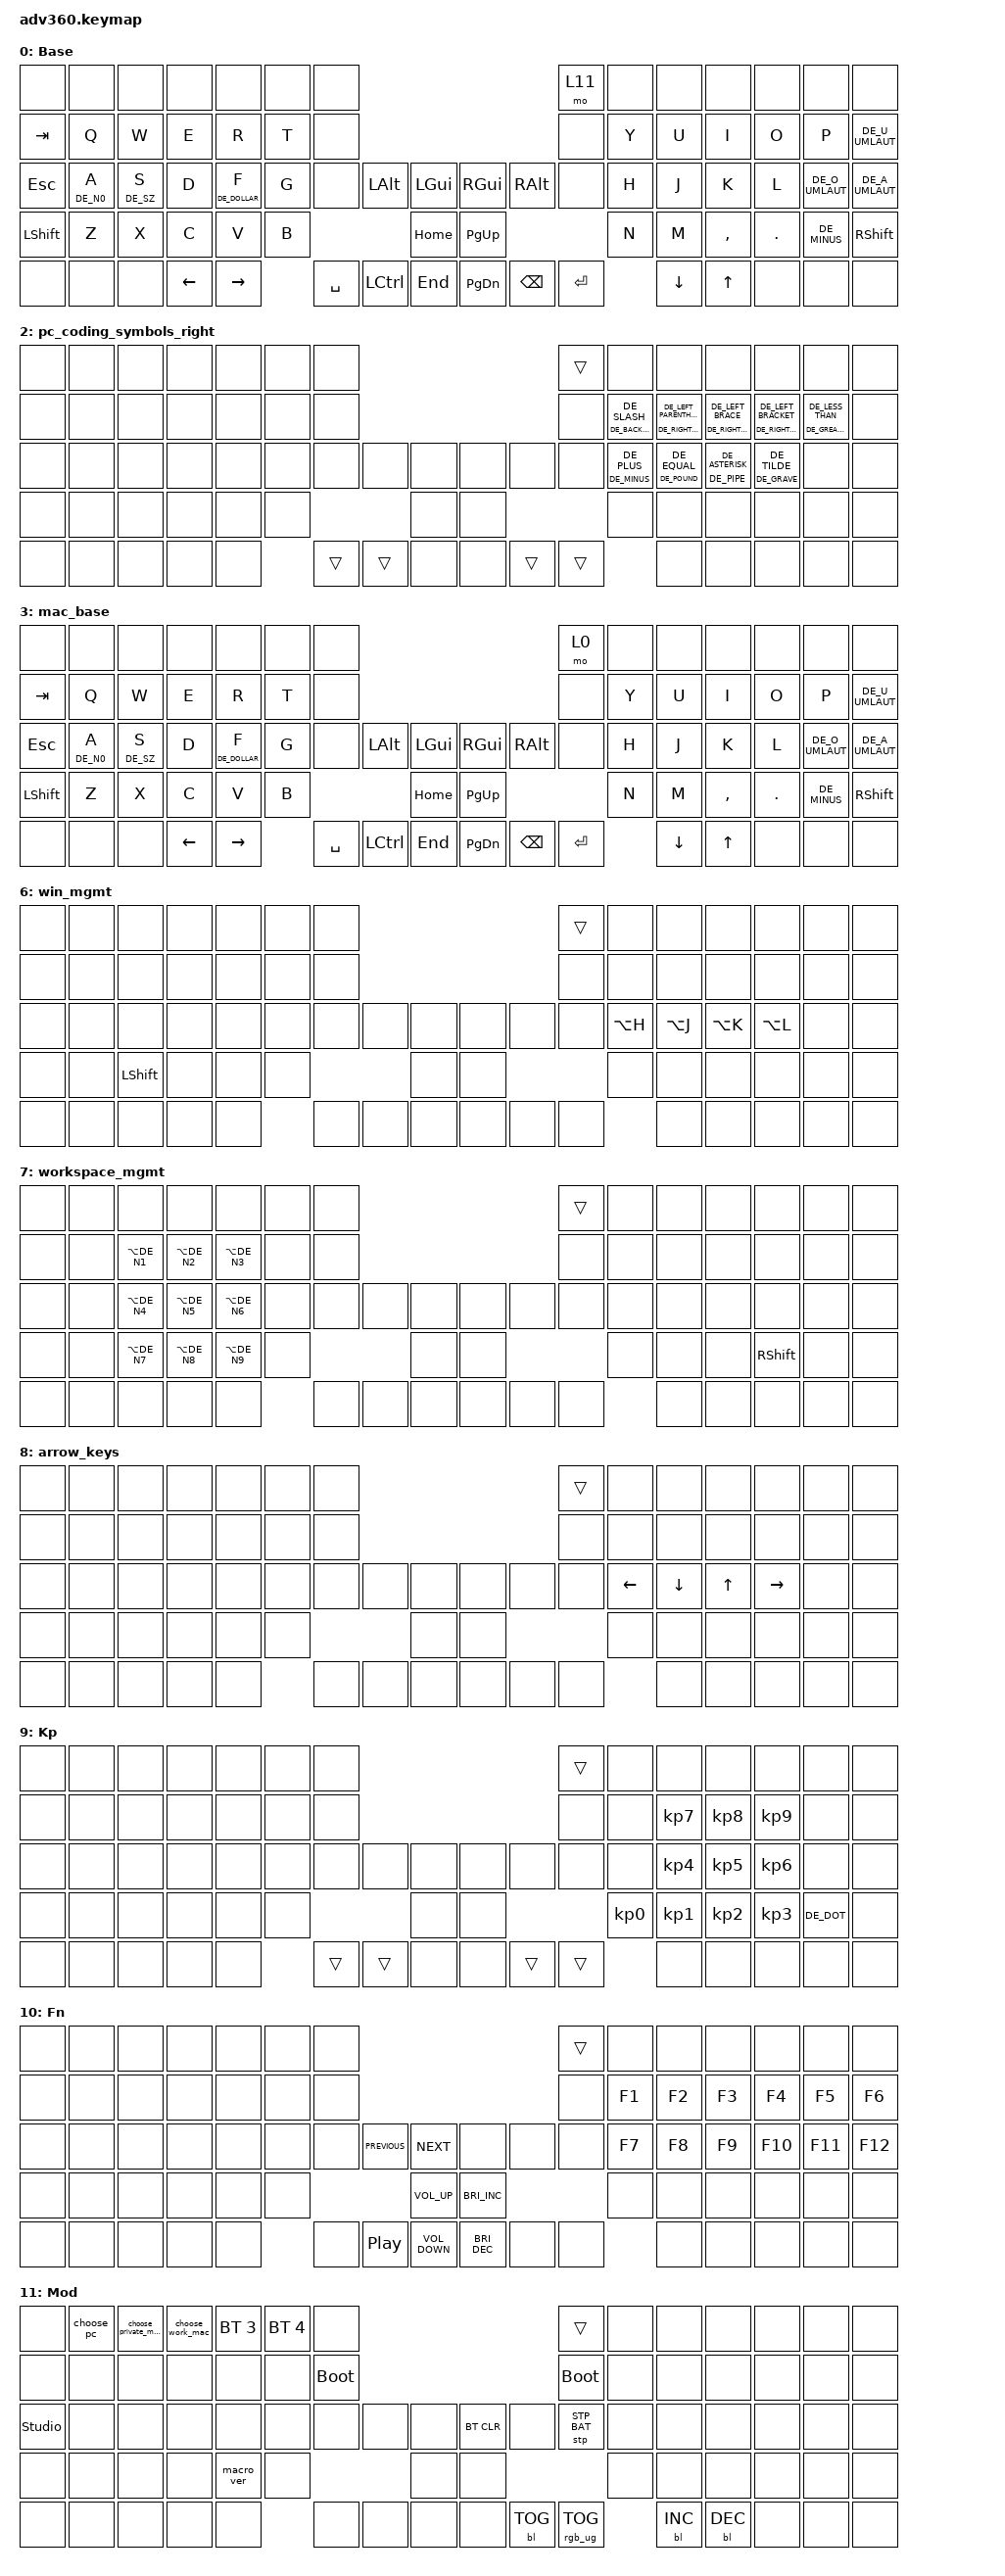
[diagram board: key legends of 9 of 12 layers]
#include <dt-bindings/zmk/stp.h>
#include <behaviors.dtsi>
#include <dt-bindings/zmk/backlight.h>
#include <dt-bindings/zmk/bt.h>
#include <dt-bindings/zmk/keys.h>
#include <dt-bindings/zmk/rgb.h>
#include "keys_de.h"

/ {
    behaviors {
        #include "macros.dtsi"
      #include "version.dtsi"

        hm: homerow_mods {
            compatible = "zmk,behavior-hold-tap";
            label = "HOMEROW_MODS";
            #binding-cells = <2>;
            tapping-term-ms = <200>;
            quick_tap_ms = <175>;
            flavor = "tap-preferred";
            bindings = <&kp>, <&kp>;
        };

        hold_alternative: hold_alternative {
            compatible = "zmk,behavior-hold-tap";
            label = "HOLD_ALTERNATIVE";
            bindings = <&kp>, <&kp>;

            #binding-cells = <2>;
            tapping-term-ms = <250>;
            flavor = "tap-preferred";
        };
    };

    macros {
        choose_work_mac: choose_mac {
            compatible = "zmk,behavior-macro";
            #binding-cells = <0>;
            bindings = <&bt BT_SEL 2 &tog 3>;
            label = "CHOOSE_MAC";
        };

        choose_pc: choose_pc {
            compatible = "zmk,behavior-macro";
            #binding-cells = <0>;
            bindings = <&bt BT_SEL 0 &tog 0>;
            label = "CHOOSE_PC";
        };

        choose_private_mac: choose_private_mac {
            compatible = "zmk,behavior-macro";
            #binding-cells = <0>;
            bindings = <&bt BT_SEL 1 &tog 3>;
            label = "CHOOSE_PRIVATE_MAC";
        };
    };

    combos {
        compatible = "zmk,combos";

        toggle_coding_symbols_right {
            bindings = <&mo 2>;
            key-positions = <32 31>;
        };

        toggle_coding_symbols_left {
            bindings = <&mo 1>;
            key-positions = <41 42>;
        };

        toggle_keypad {
            bindings = <&mo 9>;
            key-positions = <29 30>;
        };

        toggle_fn {
            bindings = <&mo 10>;
            key-positions = <47 48>;
        };

        toggle_win_mgmt {
            bindings = <&mo 9>;
            key-positions = <50 49>;
        };

        toggle_workspace_mgmt {
            bindings = <&mo 8>;
            key-positions = <55 56>;
        };

        toggle_arrow_keys {
            bindings = <&mo 9>;
            key-positions = <18 17>;
        };
    };

    keymap {
        compatible = "zmk,keymap";

        default {
            display-name = "Base";
            bindings = <
&none           &none                      &none                      &none     &none            &none  &none                                                            &mo 11     &none  &none     &none      &none    &none            &none
&kp TAB         &kp Q                      &kp W                      &kp E     &kp R            &kp T  &none                                                            &none      &kp Y  &kp U     &kp I      &kp O    &kp P            &kp DE_U_UMLAUT
&kp ESC         &hold_alternative DE_N0 A  &hold_alternative DE_SZ S  &kp D     &hm DE_DOLLAR F  &kp G  &none      &kp LEFT_ALT  &kp LGUI      &kp RGUI   &kp RIGHT_ALT  &none      &kp H  &kp J     &kp K      &kp L    &kp DE_O_UMLAUT  &kp DE_A_UMLAUT
&kp LEFT_SHIFT  &kp Z                      &kp X                      &kp C     &kp V            &kp B                           &kp HOME      &kp PG_UP                            &kp N  &kp M     &kp COMMA  &kp DOT  &kp DE_MINUS     &kp RIGHT_SHIFT
&none           &none                      &none                      &kp LEFT  &kp RIGHT               &kp SPACE  &kp LCTRL     &kp END       &kp PG_DN  &kp BACKSPACE  &kp ENTER         &kp DOWN  &kp UP     &none    &none            &none
            >;

            label = "Base";
        };

        pc_coding_symbols_left {
            display-name = "pc_coding_symbols_left";
            bindings = <
&none                              &none                                &none                                             &none             &none             &none             &none                                     &trans  &none  &none  &none  &none  &none  &none
&hold_alternative DE_DEG DE_CARET  &hold_alternative (DE_QMARK) LS(N1)  &hold_alternative (DE_SINGLE_QUOTE) LS(NUMBER_2)  &kp LS(NUMBER_4)  &kp LS(NUMBER_5)  &kp LS(NUMBER_6)  &none                                     &none   &none  &none  &none  &none  &none  &none
&none                              &none                                &none                                             &none             &none             &none             &none   &none   &none      &none  &none   &none   &none  &none  &none  &none  &none  &none
&none                              &none                                &none                                             &none             &none             &none                             &none      &none                  &none  &none  &none  &none  &none  &none
&none                              &none                                &none                                             &none             &none                               &trans  &trans  &none      &none  &trans  &trans         &none  &none  &none  &none  &none
            >;

            label = "pc_coding_symbols_left";
        };

        pc_coding_symbols_right {
            display-name = "pc_coding_symbols_right";
            bindings = <
&none  &none  &none  &none  &none  &none  &none                                     &trans  &none                                    &none                                                       &none                                           &none                                               &none                                           &none
&none  &none  &none  &none  &none  &none  &none                                     &none   &hold_alternative DE_BACKSLASH DE_SLASH  &hold_alternative DE_RIGHT_PARENTHESIS DE_LEFT_PARENTHESIS  &hold_alternative DE_RIGHT_BRACE DE_LEFT_BRACE  &hold_alternative DE_RIGHT_BRACKET DE_LEFT_BRACKET  &hold_alternative DE_GREATER_THAN DE_LESS_THAN  &none
&none  &none  &none  &none  &none  &none  &none   &none   &none      &none  &none   &none   &hold_alternative DE_MINUS DE_PLUS       &hold_alternative DE_POUND DE_EQUAL                         &hold_alternative DE_PIPE DE_ASTERISK           &hold_alternative DE_GRAVE DE_TILDE                 &none                                           &none
&none  &none  &none  &none  &none  &none                  &none      &none                  &none                                    &none                                                       &none                                           &none                                               &none                                           &none
&none  &none  &none  &none  &none         &trans  &trans  &none      &none  &trans  &trans                                           &none                                                       &none                                           &none                                               &none                                           &none
            >;

            label = "pc_coding_symbols_right";
        };

        mac_base {
            label = "mac_base";
            display-name = "mac_base";
            bindings = <
&none           &none                      &none                      &none     &none            &none  &none                                                            &mo 0      &none  &none     &none      &none    &none            &none
&kp TAB         &kp Q                      &kp W                      &kp E     &kp R            &kp T  &none                                                            &none      &kp Y  &kp U     &kp I      &kp O    &kp P            &kp DE_U_UMLAUT
&kp ESC         &hold_alternative DE_N0 A  &hold_alternative DE_SZ S  &kp D     &hm DE_DOLLAR F  &kp G  &none      &kp LEFT_ALT  &kp LGUI      &kp RGUI   &kp RIGHT_ALT  &none      &kp H  &kp J     &kp K      &kp L    &kp DE_O_UMLAUT  &kp DE_A_UMLAUT
&kp LEFT_SHIFT  &kp Z                      &kp X                      &kp C     &kp V            &kp B                           &kp HOME      &kp PG_UP                            &kp N  &kp M     &kp COMMA  &kp DOT  &kp DE_MINUS     &kp RIGHT_SHIFT
&none           &none                      &none                      &kp LEFT  &kp RIGHT               &kp SPACE  &kp LCTRL     &kp END       &kp PG_DN  &kp BACKSPACE  &kp ENTER         &kp DOWN  &kp UP     &none    &none            &none
            >;
        };

        mac_coding_symbols_left {
            label = "mac_coding_symbols_left";
            display-name = "mac_coding_symbols_left";
            bindings = <
&none                                           &none                                &none                                             &none             &none             &none             &none                                     &trans  &none  &none  &none  &none  &none  &none
&hold_alternative DE_GREATER_THAN DE_LESS_THAN  &hold_alternative (DE_QMARK) LS(N1)  &hold_alternative (DE_SINGLE_QUOTE) LS(NUMBER_2)  &kp LS(NUMBER_4)  &kp LS(NUMBER_5)  &kp LS(NUMBER_6)  &none                                     &none   &none  &none  &none  &none  &none  &none
&none                                           &none                                &none                                             &none             &none             &none             &none   &none   &none      &none  &none   &none   &none  &none  &none  &none  &none  &none
&none                                           &none                                &none                                             &none             &none             &none                             &none      &none                  &none  &none  &none  &none  &none  &none
&none                                           &none                                &none                                             &none             &none                               &trans  &trans  &none      &none  &trans  &trans         &none  &none  &none  &none  &none
            >;
        };

        mac_coding_symbols_right {
            label = "mac_coding_symbols_right";
            display-name = "mac_coding_symbols_right";
            bindings = <
&none  &none  &none  &none  &none  &none  &none                                     &trans  &none                                        &none                                                       &none                                               &none                                    &none                              &none
&none  &none  &none  &none  &none  &none  &none                                     &none   &hold_alternative RS(RA(NUMBER_7)) DE_SLASH  &hold_alternative DE_RIGHT_PARENTHESIS DE_LEFT_PARENTHESIS  &hold_alternative DE_RIGHT_BRACKET DE_LEFT_BRACKET  &hold_alternative (RA(N6)) RA(NUMBER_5)  &hold_alternative DE_DEG DE_CARET  &none
&none  &none  &none  &none  &none  &none  &none   &none   &none      &none  &none   &none   &hold_alternative DE_MINUS DE_PLUS           &hold_alternative DE_POUND DE_EQUAL                         &hold_alternative RA(NUMBER_7) DE_ASTRK             &hold_alternative DE_GRAVE PG_UP         &none                              &none
&none  &none  &none  &none  &none  &none                  &none      &none                  &none                                        &none                                                       &none                                               &none                                    &none                              &none
&none  &none  &none  &none  &none         &trans  &trans  &none      &none  &trans  &trans                                               &none                                                       &none                                               &none                                    &none                              &none
            >;
        };

        win_mgmt {
            bindings = <
&none  &none  &none           &none  &none  &none  &none                                  &trans  &none      &none      &none      &none      &none  &none
&none  &none  &none           &none  &none  &none  &none                                  &none   &none      &none      &none      &none      &none  &none
&none  &none  &none           &none  &none  &none  &none  &none  &none      &none  &none  &none   &kp LA(H)  &kp LA(J)  &kp LA(K)  &kp LA(L)  &none  &none
&none  &none  &kp LEFT_SHIFT  &none  &none  &none                &none      &none                 &none      &none      &none      &none      &none  &none
&none  &none  &none           &none  &none         &none  &none  &none      &none  &none  &none              &none      &none      &none      &none  &none
            >;

            label = "win_mgmt";
        };

        workspace_mgmt {
            bindings = <
&none  &none  &none          &none          &none          &none  &none                                  &trans  &none  &none  &none  &none            &none  &none
&none  &none  &kp LA(DE_N1)  &kp LA(DE_N2)  &kp LA(DE_N3)  &none  &none                                  &none   &none  &none  &none  &none            &none  &none
&none  &none  &kp LA(DE_N4)  &kp LA(DE_N5)  &kp LA(DE_N6)  &none  &none  &none  &none      &none  &none  &none   &none  &none  &none  &none            &none  &none
&none  &none  &kp LA(DE_N7)  &kp LA(DE_N8)  &kp LA(DE_N9)  &none                &none      &none                 &none  &none  &none  &kp RIGHT_SHIFT  &none  &none
&none  &none  &none          &none          &none                 &none  &none  &none      &none  &none  &none          &none  &none  &none            &none  &none
            >;

            label = "workspace_mgmt";
        };

        arrow_keys {
            bindings = <
&none  &none  &none  &none  &none  &none  &none                                  &trans  &none     &none     &none   &none      &none  &none
&none  &none  &none  &none  &none  &none  &none                                  &none   &none     &none     &none   &none      &none  &none
&none  &none  &none  &none  &none  &none  &none  &none  &none      &none  &none  &none   &kp LEFT  &kp DOWN  &kp UP  &kp RIGHT  &none  &none
&none  &none  &none  &none  &none  &none                &none      &none                 &none     &none     &none   &none      &none  &none
&none  &none  &none  &none  &none         &none  &none  &none      &none  &none  &none             &none     &none   &none      &none  &none
            >;

            label = "arrow_keys";
        };

        keypad {
            display-name = "Kp";
            bindings = <
&none  &none  &none  &none  &none  &none  &none                                     &trans  &none            &none      &none      &none      &none       &none
&none  &none  &none  &none  &none  &none  &none                                     &none   &none            &kp KP_N7  &kp KP_N8  &kp KP_N9  &none       &none
&none  &none  &none  &none  &none  &none  &none   &none   &none      &none  &none   &none   &none            &kp KP_N4  &kp KP_N5  &kp KP_N6  &none       &none
&none  &none  &none  &none  &none  &none                  &none      &none                  &kp KP_NUMBER_0  &kp KP_N1  &kp KP_N2  &kp KP_N3  &kp DE_DOT  &none
&none  &none  &none  &none  &none         &trans  &trans  &none      &none  &trans  &trans                   &none      &none      &none      &none       &none
            >;

            label = "keypad";
        };

        fn {
            display-name = "Fn";
            bindings = <
&none  &none  &none  &none  &none  &none  &none                                                                        &trans  &none   &none   &none   &none    &none    &none
&none  &none  &none  &none  &none  &none  &none                                                                        &none   &kp F1  &kp F2  &kp F3  &kp F4   &kp F5   &kp F6
&none  &none  &none  &none  &none  &none  &none  &kp C_PREVIOUS    &kp C_NEXT             &none                 &none  &none   &kp F7  &kp F8  &kp F9  &kp F10  &kp F11  &kp F12
&none  &none  &none  &none  &none  &none                           &kp C_VOLUME_UP        &kp C_BRIGHTNESS_INC                 &none   &none   &none   &none    &none    &none
&none  &none  &none  &none  &none         &none  &kp C_PLAY_PAUSE  &kp C_VOLUME_DOWN      &kp C_BRIGHTNESS_DEC  &none  &none           &none   &none   &none    &none    &none
            >;

            label = "fn";
        };

        mod {
            display-name = "Mod";
            bindings = <
&none           &choose_pc  &choose_private_mac  &choose_work_mac  &bt BT_SEL 3  &bt BT_SEL 4  &none                                                  &trans           &none  &none       &none       &none  &none  &none
&none           &none       &none                &none             &none         &none         &bootloader                                            &bootloader      &none  &none       &none       &none  &none  &none
&studio_unlock  &none       &none                &none             &none         &none         &none        &none  &none      &bt BT_CLR  &none       &stp STP_BAT     &none  &none       &none       &none  &none  &none
&none           &none       &none                &none             &macro_ver    &none                             &none      &none                                    &none  &none       &none       &none  &none  &none
&none           &none       &none                &none             &none                       &none        &none  &none      &none       &bl BL_TOG  &rgb_ug RGB_TOG         &bl BL_INC  &bl BL_DEC  &none  &none  &none
            >;

            label = "mod";
        };
    };

    conditional_layers {
        compatible = "zmk,conditional-layers";

        cond_adjust_symbols_left {
            if-layers = <3 1>;
            then-layer = <4>;
        };

        cond_adjust_symbols_right {
            if-layers = <3 2>;
            then-layer = <5>;
        };
    };
};
